# PIC32CK1025SG00064 register map
Vendor: Microchip Technology; Series: PIC32CKSG00; File version: 0
CPU: CM33 r0p0, little endian, MPU, FPU, DSP, 3 interrupt priority bits, 158 interrupts, 19 SAU regions
Registers are 32-bit, read-write, reset 0x0 unless marked. A register's access mark holds for its fields unless they carry their own. Offsets are from the block's base; [hi:lo] are bit positions; lines under a group give offsets from that group; {n}, {i} and the like mark numbered series; 'fields as' and 'values as' point back to an identical list.

## EIC — External Interrupt Controller
Base 0x4401A000; register names take the prefix EIC_
Same registers: EIC_SEC 0x4401B000 (register names take the prefix EIC_SEC_)
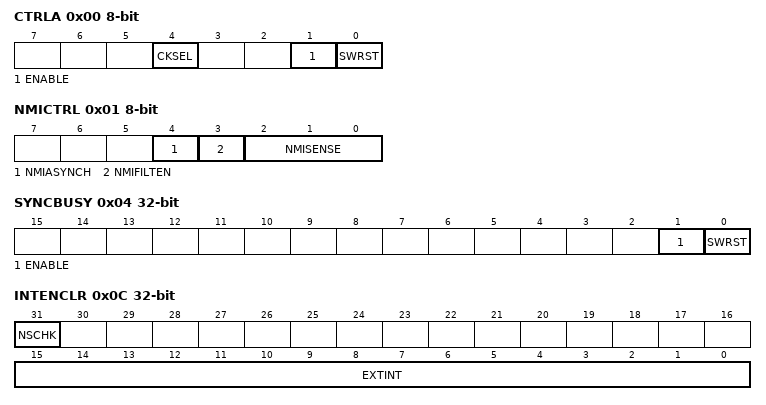
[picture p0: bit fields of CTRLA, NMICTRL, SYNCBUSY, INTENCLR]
0x00 CTRLA 8-bit — Control A
  [4] CKSEL — Clock Selection
    0=CLK_GCLK (Clocked by GCLK); 1=CLK_ULP32K (Clocked by ULP32K)
  [1] ENABLE
  [0] SWRST — Software Reset
0x01 NMICTRL 8-bit — Non-Maskable Interrupt Control
  [4] NMIASYNCH — Asynchronous Edge Detection Mode
    0=SYNC (Edge detection is clock synchronously operated); 1=ASYNC (Edge detection is clock asynchronously operated)
  [3] NMIFILTEN — Non-Maskable Interrupt Filter Enable
  [2:0] NMISENSE — Non-Maskable Interrupt Sense Configuration
    0=NONE (No detection); 1=RISE (Rising-edge detection); 2=FALL (Falling-edge detection); 3=BOTH (Both-edges detection); 4=HIGH (High-level detection); 5=LOW (Low-level detection)
0x02 NMIFLAG 16-bit — Non-Maskable Interrupt Flag Status and Clear
  [0] NMI — Non-Maskable Interrupt
0x04 SYNCBUSY ro — Synchronization Busy
  [1] ENABLE — Enable Synchronization Busy Status
  [0] SWRST — Software Reset Synchronization Busy Status
0x08 EVCTRL — Event Control
  [15:0] EXTINTEO — External Interrupt Event Output Enable
0x0C INTENCLR — Interrupt Enable Clear
  [31] NSCHK — Non-secure Check Interrupt Enable
  [15:0] EXTINT — External Interrupt Enable
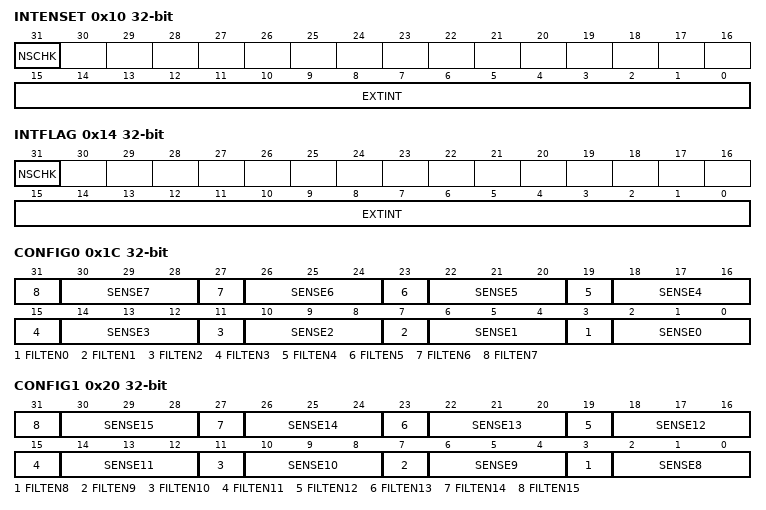
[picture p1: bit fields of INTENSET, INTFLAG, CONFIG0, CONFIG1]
0x10 INTENSET — Interrupt Enable Set
  fields as INTENCLR
0x14 INTFLAG — Interrupt Flag Status and Clear
  [31] NSCHK — Non-secure Check Interrupt
  [15:0] EXTINT — External Interrupt
0x18 ASYNCH — External Interrupt Asynchronous Mode
  [15:0] ASYNCH — Asynchronous Edge Detection Mode
    values as NMICTRL.NMIASYNCH
0x1C CONFIG0 — External Interrupt Sense Configuration
  [4n+3] FILTEN{n} (n=0..7) — Filter Enable {n}
  [4n+2:4n] SENSE{n} (n=0..7) — Input Sense Configuration {n}
    0=NONE (No detection); 1=RISE (Rising edge detection); 2=FALL (Falling edge detection); 3=BOTH (Both edges detection); 4=HIGH (High level detection); 5=LOW (Low level detection)
0x20 CONFIG1 — External Interrupt Sense Configuration
  [4n-29] FILTEN{n} (n=8..15) — Filter Enable {n}
  [4n-30:4n-32] SENSE{n} (n=8..15) — Input Sense Configuration {n}
    values as CONFIG0.SENSE0
0x30 DEBOUNCEN — Debouncer Enable
  [15:0] DEBOUNCEN
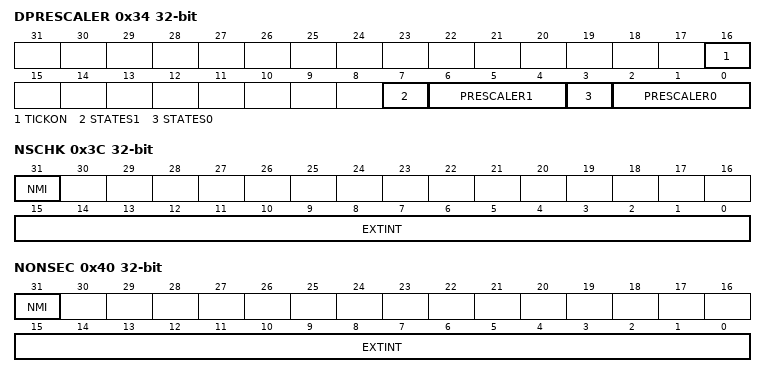
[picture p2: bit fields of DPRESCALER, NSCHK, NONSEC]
0x34 DPRESCALER — Debouncer Prescaler
  [16] TICKON — Pin Sampler frequency selection
    0=CLK_GCLK_EIC (Clocked by GCLK); 1=CLK_LFREQ (Clocked by Low Frequency Clock)
  [7] STATES1 — Debouncer number of states
    0=LFREQ3 (3 low frequency samples); 1=LFREQ7 (7 low frequency samples)
  [6:4] PRESCALER1 — Debouncer Prescaler
    0=DIV2 (EIC clock divided by 2); 1=DIV4 (EIC clock divided by 4); 2=DIV8 (EIC clock divided by 8); 3=DIV16 (EIC clock divided by 16); 4=DIV32 (EIC clock divided by 32); 5=DIV64 (EIC clock divided by 64); 6=DIV128 (EIC clock divided by 128); 7=DIV256 (EIC clock divided by 256)
  [3] STATES0 — Debouncer number of states
    values as STATES1
  [2:0] PRESCALER0 — Debouncer Prescaler
    values as PRESCALER1
0x38 PINSTATE ro
  [15:0] PINSTATE
0x3C NSCHK — Non-secure Interrupt Check Enable
  [31] NMI — Non-Maskable External Interrupt Nonsecure Check Enable
  [15:0] EXTINT — External Interrupt Nonsecure Check Enable
0x40 NONSEC — Non-secure Interrupt
  [31] NMI — Non-Maskable Interrupt Nonsecure Enable
  [15:0] EXTINT — External Interrupt Nonsecure Enable

## EVSYS — Event System Interface
Base 0x4480E000; register names take the prefix EVSYS_
0x00 CTRLA 8-bit wo — Control
  [0] SWRST — Software Reset
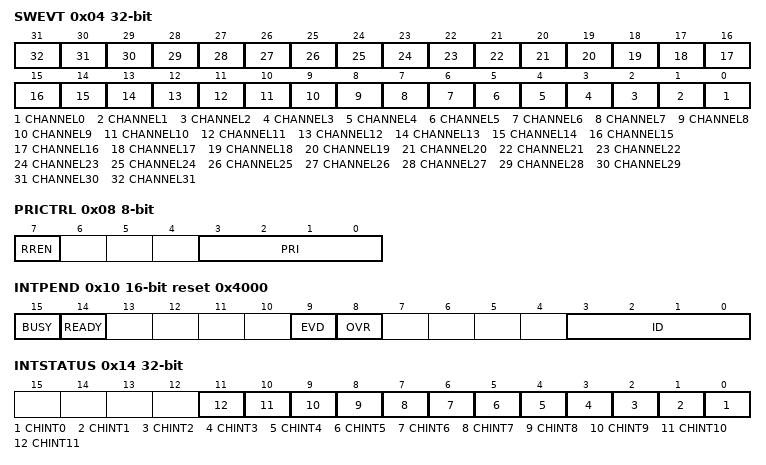
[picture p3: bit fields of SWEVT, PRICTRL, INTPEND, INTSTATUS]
0x04 SWEVT wo — Software Event
  [n] CHANNEL{n} (n=0..31) — Channel {n} Software Selection
0x08 PRICTRL 8-bit — Priority Control
  [7] RREN — Round-Robin Scheduling Enable
  [3:0] PRI — Channel Priority Number
0x10 INTPEND 16-bit reset 0x4000 — Channel Pending Interrupt
  [15] BUSY
  [14] READY
  [9] EVD — Channel Event Detected
  [8] OVR — Channel Overrun
  [3:0] ID — Channel ID
0x14 INTSTATUS ro — Interrupt Status
  [n] CHINT{n} (n=0..11) — Channel {n} Pending Interrupt
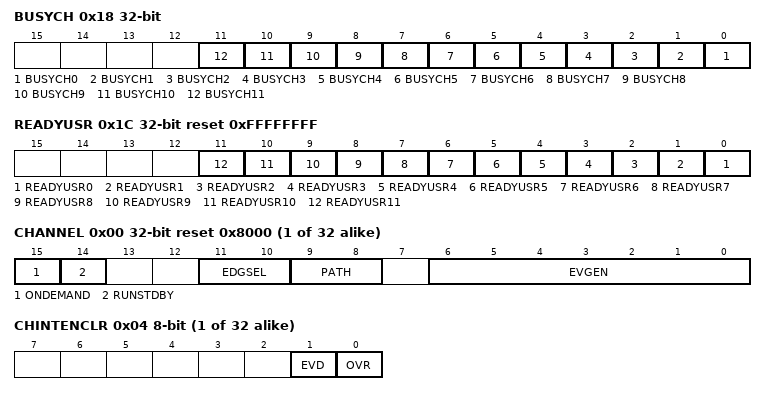
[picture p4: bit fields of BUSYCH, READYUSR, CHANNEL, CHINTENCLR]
0x18 BUSYCH ro — Busy Channels
  [n] BUSYCH{n} (n=0..11) — Busy Channel {n}
0x1C READYUSR ro reset 0xFFFFFFFF — Ready Users
  [n] READYUSR{n} (n=0..11) — Ready User for Channel {n}
{0x20+8i} CHANNEL[{i}] (i=0..31) group
  0x00 CHANNEL reset 0x8000 — Channel n Control
    [15] ONDEMAND — Generic Clock On Demand
    [14] RUNSTDBY — Run in standby
    [11:10] EDGSEL — Edge Detection Selection
      0=NO_EVT_OUTPUT (No event output when using the resynchronized or synchronous path); 1=RISING_EDGE (Event detection only on the rising edge of the signal from the event generator when using the resynchronized or synchronous path); 2=FALLING_EDGE (Event detection only on the falling edge of the signal from the event generator when using the resynchronized or synchronous path); 3=BOTH_EDGES (Event detection on rising and falling edges of the signal from the event generator when using the resynchronized or synchronous path)
    [9:8] PATH — Path Selection
      0=ASYNCHRONOUS (Asynchronous path); 1=RESYNCHRONIZED (Resynchronized path)
    [6:0] EVGEN — Event Generator Selection
  0x04 CHINTENCLR 8-bit — Channel n Interrupt Enable Clear
    [1] EVD — Channel Event Detected Interrupt Disable
    [0] OVR — Channel Overrun Interrupt Disable
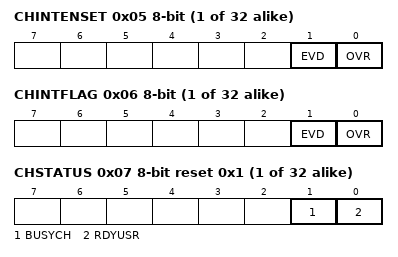
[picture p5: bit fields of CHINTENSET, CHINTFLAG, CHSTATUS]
  0x05 CHINTENSET 8-bit — Channel n Interrupt Enable Set
    [1] EVD — Channel Event Detected Interrupt Enable
    [0] OVR — Channel Overrun Interrupt Enable
  0x06 CHINTFLAG 8-bit — Channel n Interrupt Flag Status and Clear
    [1] EVD — Channel Event Detected
    [0] OVR — Channel Overrun
  0x07 CHSTATUS 8-bit ro reset 0x1 — Channel n Status
    [1] BUSYCH — Busy Channel
    [0] RDYUSR — Ready User
{0x120+i} USER[{i}] (i=0..103) 8-bit — User Multiplexer n
  [5:0] CHANNEL — Channel Event Selection

## Notices in the file
Copyright (c) 2022 Microchip Technology Inc.
SPDX-License-Identifier: Apache-2.0
Licensed under the Apache License, Version 2.0 (the "License");
you may not use this file except in compliance with the License.
You may obtain a copy of the License at
http://www.apache.org/licenses/LICENSE-2.0
Unless required by applicable law or agreed to in writing, software
distributed under the License is distributed on an "AS IS" BASIS,
WITHOUT WARRANTIES OR CONDITIONS OF ANY KIND, either express or implied.
See the License for the specific language governing permissions and
limitations under the License.
